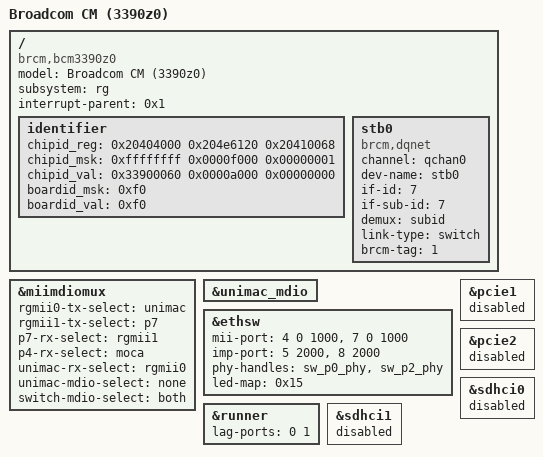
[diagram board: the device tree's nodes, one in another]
/dts-v1/;

/ {
	model = "Broadcom CM (3390z0)";
	compatible = "brcm,bcm3390z0", "brcm,brcmstb";
	subsystem = "rg";
	#address-cells = <0x2>;
	#size-cells = <0x2>;
	interrupt-parent = <0x1>;

	identifier {
			    /* chip id    mfg id     don't park */
		chipid_reg = < 0x20404000 0x204e6120 0x20410068 >;
		chipid_msk = < 0xffffffff 0x0000f000 0x00000001 >;
		chipid_val = < 0x33900060 0x0000a000 0x00000000 >;
			     /* 7278VMS  */
		boardid_msk = < 0xf0 >;
		boardid_val = < 0xf0 >;
	};
};

/include/ "rg.3390b0-bolt.dtsi"
/include/ "rg.3390z0-bolt.dtsi"
/include/ "rg.3390-base.dtsi"
/include/ "rg.3390-wifi.dtsi"

/********************************************************************
 * any nodes that appear below are platform specific additions and
 * replacements.
 * The dtc will add or replace any properties in the nodes
 * below to the same nodes that appear in include files above.
 * If the property does not exist in the node above it will be added.
 * If the property does exist it will replace it.
 ********************************************************************/
/ {
	stb0 {
		compatible = "brcm,dqnet";
		channel = <&qchan0>;
		dev-name = "stb0";
		if-id = <7>;		/* rdpa_if_lan5 */
		if-sub-id = <7>;	/* if-sub-id is the switch port number */
		demux = "subid";
		link-type = "switch";
		brcm-tag = <1>;
	};
};

&miimdiomux {
	rgmii0-tx-select = "unimac";
	rgmii1-tx-select = "p7";
	p7-rx-select = "rgmii1";
	p4-rx-select = "moca";
	unimac-rx-select = "rgmii0";
	unimac-mdio-select = "none";
	switch-mdio-select = "both";
};

&unimac_mdio {
	compatible = "";
};

&ethsw {
	mii-port   = <4 0 1000>,
		     <7 0 1000>;
	imp-port   = <5 2000>,
		     <8 2000>;
	phy-handles = <&sw_p0_phy>,
		      <&sw_p2_phy>;
	led-map = < 0x15 >;
};

&runner {
	lag-ports = < 0 1 >;
};

&pcie1 {
	status = "disabled";
};

&pcie2 {
	status = "disabled";
};

&sdhci0 {
	status = "disabled";
};

&sdhci1 {
	status = "disabled";
};
